# cslr_emifa register map
Vendor: Texas Instruments
Peripheral module from a debugger description file.
Registers are 32-bit, access per field, reset 0x0 unless marked. A register's access mark holds for its fields unless they carry their own. Offsets are as the file gives them; lines under a group give offsets from that group; [hi:lo] are bit positions; {n}, {i} and the like mark numbered series; 'fields as' and 'values as' point back to an identical list; <NAME> marks a mode.

## EMIFA — This module provides an interface between the DSP and external memory devices like async and sync memory devices.
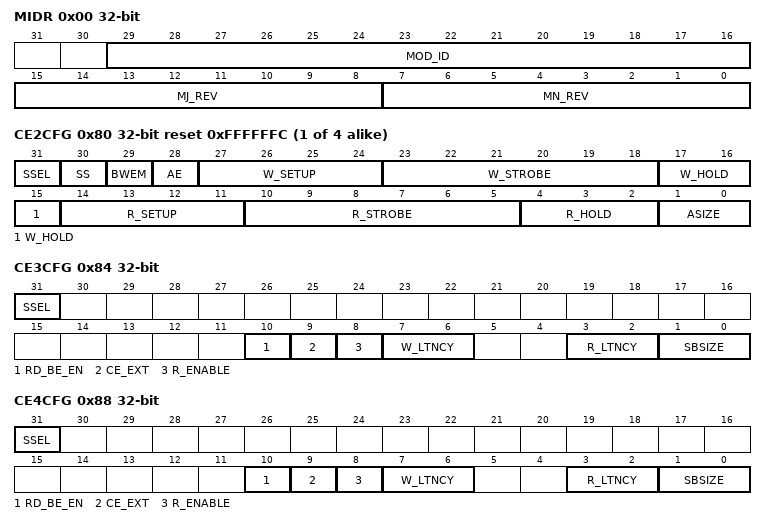
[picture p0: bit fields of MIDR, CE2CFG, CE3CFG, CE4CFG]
0x00 MIDR ro — This register reflects the latest changes made to the memory controller.
  [29:16] MOD_ID — EMIF module ID
  [15:8] MJ_REV — Major Revision
  [7:0] MN_REV — Minor Revision
0x04 STAT ro — This register reflects the configuration of the EMIF.
  [31] BE — Big Endian. Reflects whether the EMIF is configured for big or little endian mode.
    1=B_ENDIAN (EMIF is configured for big endian mode.); 0=L_ENDIAN (EMIF is configured for little endian mode.)
0x20 BPRIO reset 0xFF — Used to temporarily raise priority of old commands.
  [7:0] PRIO_RAISE rw — Number of memory transfers after which the EMIF momentarily raises the priority of old commands in the command FIFO.
{0x78+4i} CE{i}CFG rw reset 0xFFFFFFC (i=2..5) — Selects the access type and configures the access parameters for the CE{i} space. Register description when SSEL = 0.
  [31] SSEL — Synchronous/asynchronous memory select. This bit specifies whether CE{i} is configured for synchronous or asynchronous memory accesses. The other fields in this table define the bits in the CE{i}CFG when SSEL is cleared to 0 (asynchronous memory mode).
    1=SYNCMEM (Synchronous memory mode); 0=ASYNCMEM (Asynchronous memory mode)
  [30] SS — Select Strobe mode enable. When set to 1, the CE{i} pin will have read and write strobe timing.
    1=SSMEN (Select strobe mode enabled); 0=SSMDIS (Select strobe mode disabled)
  [29] BWEM — WE Strobe mode enable. When set to 1, the BE[7:0] output pins will act as active low byte write enables when accessing CE{i} space. When cleared to 0, the BE[7:0] output pins will act as active low byte enables when accessing CE{i}.
    1=WESEN (WE Strobe mode enabled); 0=WESDIS (WE Strobe mode disabled)
  [28] AE — Asynchronous ready input enable. Set to 1 to enable the asynchronous ready (ARDY) input pin during accesses to the CE{i} space. When enabled, the ARDY pin can be used to extend the strobe period during asynchronous accesses .
    1=ARDYEN (ARDY pin enabled); 0=ARDYDIS (ARDY pin disabled)
  [27:24] W_SETUP — Write setup width. Number of ECLKOUT cycles from EA[19:0], BA[1:0], D[63:0], BE[7:0], and CE{i} being set to AWEz asserted, minus one cycle.
  [23:18] W_STROBE — Write strobe width. Number of ECLKOUT cycles for which AWEz is held active, minus one cycle.
  [17:15] W_HOLD — Write hold width. Number of ECLKOUT cycles for which EA[19:0], BA[1:0], D[63:0], BE[7:0], and CE{i} are held after AWEz has been deasserted, minus one cycle.
  [14:11] R_SETUP — Read setup width. Number of ECLKOUT cycles from EA[19:0], BA[1:0], BE[7:0], and CE{i} being set to AOEz asserted, minus one cycle.
  [10:5] R_STROBE — Read strobe width. Number of ECLKOUT cycles for which AOEz is held active, minus one cycle.
  [4:2] R_HOLD — Read hold width. Number of ECLKOUT cycles for which EA[19:0], BA[1:0], BE[7:0], and CE{i} are held after AOEz has been deasserted, minus one cycle.
  [1:0] ASIZE — Asynchronous Memory Size. Defines the width of the asynchronous device's data bus.
    0=8BIT (8-bit data bus.); 1=16BIT (16-bit data bus.); 2=32BIT (32-bit data bus.); 3=64BIT (64-bit data bus.)
0x80 CE2CFG — Selects the access type and configures the access parameters for the CE2 space. Register description when SSEL = 1.
  [31] SSEL rw — Synchronous/asynchronous memory select. This bit specifies whether CE2 is configured for synchronous or asynchronous memory accesses. The other fields in this table define the bits in the CE2CFG when SSEL is set to 1 (synchronous memory mode).
    values as SSEL
  [10] RD_BE_EN rw — Read Byte Enable Enable. If set to 1, the byte enable pins (BE[7:0]) are driven during synchronous memory reads. If cleared to 0, BE[7:0] stay high during synchronous memory reads. Not supported for R_LTNCY = 0.
    1=SET (Byte enables are driven during synchronous memory reads.); 0=CLR (Byte enables stay high during synchronous memroy reads.)
  [9] CE_EXT rw — Synchronous Memory Chip Enable Extend. Defines the behavior of the CE2 pin during synchronous accesses.
    1=SET (CE2 goes active when SOEz goes active and will stay active until SOEz goes inactive. The timing of SOEz is controlled by R_LTNCY. Used for synchronous FIFO interfaces where CEz gates SOEz.); 0=CLR (CE2 goes inactive after final command has been issued.)
  [8] R_ENABLE rw — Synchronous Memory Read Enable Mode. Defines the behavior of the SADSz/SREz signal during synchronous accesses.
    1=SET (The SADSz/SREz pin acts as SREz. The SREz pin goes low only for reads. No deselect command is issued. Used for FIFO interfaces.); 0=CLR (The SADSz/SREz pin acts as the SADSz pin. The SADSz pin goes active low for reads and writes. A deselect command is issued by driving SADSz active high after a command if no new command is pending for the same CE space. Used for SBSRAM and ZBT devices.)
  [7:6] W_LTNCY rw — Synchronous Memory Write Latency. Defines the synchronous device's write latency in EMIF clock cycles.
    0=ZEROCYCLE (0 cycle write latency); 1=ONECYCLE (1 cycle write latency); 2=TWOCYCLE (2 cycle write latency); 3=THREECYCLE (3 cycle write latency)
  [3:2] R_LTNCY rw — Synchronous Memory Read Latency. Defines the synchronous device's read latency in EMIF clock cycles. Read latency of 0 is not supported.
    1=ONECYCLE (1 cycle read latency); 2=TWOCYCLE (2 cycle read latency); 3=THREECYCLE (3 cycle read latency)
  [1:0] SBSIZE rw — Synchronous Memory Device Size. Defines the width of the synchronous device's data bus.
    values as ASIZE
0x84 CE3CFG — Selects the access type and configures the access parameters for the CE3 space. Register description when SSEL = 1.
  [31] SSEL rw — Synchronous/asynchronous memory select. This bit specifies whether CE3 is configured for synchronous or asynchronous memory accesses. The other fields in this table define the bits in the CE3CFG when SSEL is set to 1 (synchronous memory mode).
    values as CE2CFG.SSEL
  [10] RD_BE_EN rw — Read Byte Enable Enable. If set to 1, the byte enable pins (BE[7:0]) are driven during synchronous memory reads. If cleared to 0, BE[7:0] stay high during synchronous memory reads. Not supported for R_LTNCY = 0.
    1=SET (Byte enables are driven during synchronous memory reads.); 0=CLR (Byte enables stay high during synchronous memroy reads.)
  [9] CE_EXT rw — Synchronous Memory Chip Enable Extend. Defines the behavior of the CE3 pin during synchronous accesses.
    1=SET (CE3 goes active when SOEz goes active and will stay active until SOEz goes inactive. The timing of SOEz is controlled by R_LTNCY. Used for synchronous FIFO interfaces where CEz gates SOEz.); 0=CLR (CE3 goes inactive after final command has been issued.)
  [8] R_ENABLE rw — Synchronous Memory Read Enable Mode. Defines the behavior of the SADSz/SREz signal during synchronous accesses.
    1=SET (The SADSz/SREz pin acts as SREz. The SREz pin goes low only for reads. No deselect command is issued. Used for FIFO interfaces.); 0=CLR (The SADSz/SREz pin acts as the SADSz pin. The SADSz pin goes active low for reads and writes. A deselect command is issued by driving SADSz active high after a command if no new command is pending for the same CE space. Used for SBSRAM and ZBT devices.)
  [7:6] W_LTNCY rw — Synchronous Memory Write Latency. Defines the synchronous device's write latency in EMIF clock cycles.
    0=ZEROCYCLE (0 cycle write latency); 1=ONECYCLE (1 cycle write latency); 2=TWOCYCLE (2 cycle write latency); 3=THREECYCLE (3 cycle write latency)
  [3:2] R_LTNCY rw — Synchronous Memory Read Latency. Defines the synchronous device's read latency in EMIF clock cycles. Read latency of 0 is not supported.
    1=ONECYCLE (1 cycle read latency); 2=TWOCYCLE (2 cycle read latency); 3=THREECYCLE (3 cycle read latency)
  [1:0] SBSIZE rw — Synchronous Memory Device Size. Defines the width of the synchronous device's data bus.
    values as CE2CFG.ASIZE
0x88 CE4CFG — Selects the access type and configures the access parameters for the CE4 space. Register description when SSEL = 1.
  [31] SSEL rw — Synchronous/asynchronous memory select. This bit specifies whether CE4 is configured for synchronous or asynchronous memory accesses. The other fields in this table define the bits in the CE4CFG when SSEL is set to 1 (synchronous memory mode).
    values as CE2CFG.SSEL
  [10] RD_BE_EN rw — Read Byte Enable Enable. If set to 1, the byte enable pins (BE[7:0]) are driven during synchronous memory reads. If cleared to 0, BE[7:0] stay high during synchronous memory reads. Not supported for R_LTNCY = 0.
    1=SET (Byte enables are driven during synchronous memory reads.); 0=CLR (Byte enables stay high during synchronous memory reads.)
  [9] CE_EXT rw — Synchronous Memory Chip Enable Extend. Defines the behavior of the CE4 pin during synchronous accesses.
    1=SET (CE4 goes active when SOEz goes active and will stay active until SOEz goes inactive. The timing of SOEz is controlled by R_LTNCY. Used for synchronous FIFO interfaces where CEz gates SOEz.); 0=CLR (CE4 goes inactive after final command has been issued.)
  [8] R_ENABLE rw — Synchronous Memory Read Enable Mode. Defines the behavior of the SADSz/SREz signal during synchronous accesses.
    values as CE3CFG.R_ENABLE
  [7:6] W_LTNCY rw — Synchronous Memory Write Latency. Defines the synchronous device's write latency in EMIF clock cycles.
    values as CE3CFG.W_LTNCY
  [3:2] R_LTNCY rw — Synchronous Memory Read Latency. Defines the synchronous device's read latency in EMIF clock cycles. Read latency of 0 is not supported.
    values as CE3CFG.R_LTNCY
  [1:0] SBSIZE rw — Synchronous Memory Device Size. Defines the width of the synchronous device's data bus.
    values as CE2CFG.ASIZE
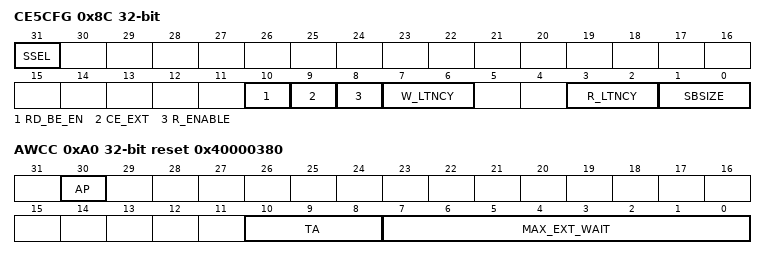
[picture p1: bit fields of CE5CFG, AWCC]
0x8C CE5CFG — Selects the access type and configures the access parameters for the CE5 space. Register description when SSEL = 1.
  [31] SSEL rw — Synchronous/asynchronous memory select. This bit specifies whether CE5 is configured for synchronous or asynchronous memory accesses. The other fields in this table define the bits in the CE5CFG when SSEL is set to 1 (synchronous memory mode).
    values as CE2CFG.SSEL
  [10] RD_BE_EN rw — Read Byte Enable Enable. If set to 1, the byte enable pins (BE[7:0]) are driven during synchronous memory reads. If cleared to 0, BE[7:0] stay high during synchronous memory reads. Not supported for R_LTNCY = 0.
    values as CE4CFG.RD_BE_EN
  [9] CE_EXT rw — Synchronous Memory Chip Enable Extend. Defines the behavior of the CE5 pin during synchronous accesses.
    1=SET (CE5 goes active when SOEz goes active and will stay active until SOEz goes inactive. The timing of SOEz is controlled by R_LTNCY. Used for synchronous FIFO interfaces where CEz gates SOEz.); 0=CLR (CE5 goes inactive after final command has been issued.)
  [8] R_ENABLE rw — Synchronous Memory Read Enable Mode. Defines the behavior of the SADSz/SREz signal during synchronous accesses.
    values as CE3CFG.R_ENABLE
  [7:6] W_LTNCY rw — Synchronous Memory Write Latency. Defines the synchronous device's write latency in EMIF clock cycles.
    values as CE3CFG.W_LTNCY
  [3:2] R_LTNCY rw — Synchronous Memory Read Latency. Defines the synchronous device's read latency in EMIF clock cycles. Read latency of 0 is not supported.
    values as CE3CFG.R_LTNCY
  [1:0] SBSIZE rw — Synchronous Memory Device Size. Defines the width of the synchronous device's data bus.
    values as CE2CFG.ASIZE
0xA0 AWCC reset 0x40000380 — Controls asynchronous memory access features.
  [30] AP rw — Asynchronous ready (ARDY) pin polarity. Defines the polarity of the ARDY pin.
    1=ACTHIGH (ARDY pin is active-high (strobe period extended when ARDY is high)); 0=ACTLOW (ARDY pin is active-low (strobe period extended when ARDY is low))
  [10:8] TA rw — Turn Around cycles. Number of ECLKOUT cycles between the end of one asynchronous memory access and the start of another asynchronous memory access, minus one cycle.
  [7:0] MAX_EXT_WAIT rw — Maximum Extended Wait cycles. The value in this field defines the number of 16 EMIF cycle periods the EMIF will wait for an extended asynchronous cycle before the cycle is terminated.
0xC0 INTRAW — Displays the status of the EMIF interrupt regarless of whether or not interrupt is enabled.
  [0] AT rw — Asynchronous timeout interrupt. Set to 1 by the EMIF to indicate that the ARDY pin did not go inactive within the number of cycles defined by the MAX_EXT_WAIT field in the Async Wait Cycle Configuration register (AWCC). Writing a 1 will clear this bit as well as the AT_MASKED bit in the Interrupt Masked register (INTMSK). Writing a 0 has no effect.
    1=SET (An asynchronous access timeout has occurred.); 0=CLEAR (An asynchronous access timeout has not occurred.)
0xC4 INTMSK — Displays the status of the EMIF interrupt only when interrupt is enabled.
  [0] AT_MASKED rw — Asynchronous timeout interrupt masked. Set to 1 by the EMIF to indicate that the ARDY pin did not go inactive within the number of cycles defined by the MAX_EXT_WAIT field in the Asynchronous Wait Cycle Configuration register (AWCC) only if the AT_MASK_SET bit in the Interrupt Mask Set register is set to 1. Writing a 1 will clear this bit as well as the AT bit in the Interrupt Raw register (INTRAW). Writing a 0 has no effect.
    values as INTRAW.AT
0xC8 INTMSKSET — Enables the EMIF interrupt.
  [0] AT_MASK_SET rw — Mask set for AT_MASKED bit in the Interrupt Masked register. Writing a 1 to this bit will enable the interrupt and set this bit as well as the AT_MASK_CLR bit in the Interrupt Mask Set register. Writing a 0 has no effect.
    1=SET (The asynchronous access timeout interrupt is enabled.); 0=CLEAR (The asynchronous access timeout interrupt is disabled.)
0xCC INTMSKCLR — Disables the EMIF interrupt.
  [0] AT_MASK_CLR rw — Mask clear for AT_MASKED bit in the Interrupt Masked register. Writing a 1 to this bit will disable the interrupt and clear this bit as well as the AT_MASK_SET bit in the Interrupt Mask Set register. Writing a 0 has no effect.
    values as INTMSKSET.AT_MASK_SET
